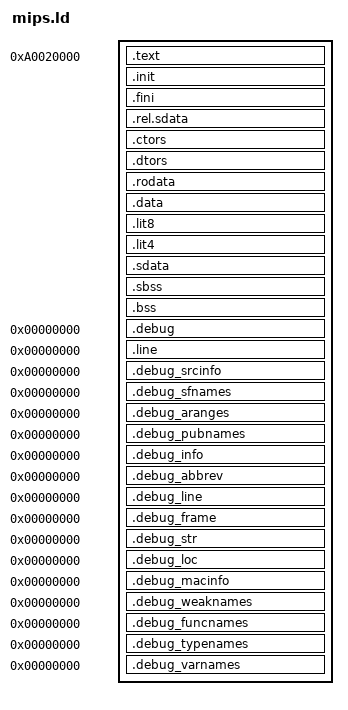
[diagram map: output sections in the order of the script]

ENTRY(_start)
OUTPUT_FORMAT("elf32-bigmips", "elf32-bigmips", "elf32-littlemips")
GROUP(-lc -lidt -lgcc)
SEARCH_DIR(.)
__DYNAMIC  =  0;

/*
 * Allocate the stack to be at the top of memory, since the stack
 * grows down
 */
PROVIDE (__stack = 0);
/* PROVIDE (__global = 0); */

SECTIONS
{	
  . = 0xA0020000;
  .text : {
    _ftext = . ;
    PROVIDE (eprol = .);
    *(.text)
    *(.text.*)
    *(.gnu.linkonce.t*)
    *(.mips16.fn.*)
    *(.mips16.call.*)
  }
  .init : {
    *(.init)
  }
  .fini : {
    *(.fini)
  }
  .rel.sdata : {
    PROVIDE (__runtime_reloc_start = .);
    *(.rel.sdata)
    PROVIDE (__runtime_reloc_stop = .);
  }
  PROVIDE (etext = .);
  _etext  =  .;
  
  .ctors    :
  {
  }

  .dtors    :
  {
  }

  . = .;
  .rodata : {
    *(.rdata)
    *(.rodata)
    *(.rodata.*)
    *(.gnu.linkonce.r*)
  }
   _fdata = ALIGN(16);
  .data : {
    *(.data)
    *(.data.*)
    *(.gnu.linkonce.d*)
  }
  . = ALIGN(8);
  _gp = . + 0x8000;
  __global = _gp;
  .lit8 : {
    *(.lit8)
  }
  .lit4 : {
    *(.lit4)
  }
  .sdata : {
    *(.sdata)
    *(.sdata.*)
    *(.gnu.linkonce.s*)
  }
  . = ALIGN(4);
   PROVIDE (edata  =  .);
   _edata  =  .;
   _fbss = .;
  .sbss : {
    *(.sbss)
    *(.scommon)
  }
  .bss : {
    _bss_start = . ;
    *(.bss)
    *(COMMON)
  }

  PROVIDE (end = .);
  _end = .;

  /* DWARF debug sections.
     Symbols in the DWARF debugging sections are relative to 
     the beginning of the section so we begin them at 0.  */

  /* DWARF 1 */
  .debug          0 : { *(.debug) }
  .line           0 : { *(.line) }

  /* GNU DWARF 1 extensions */
  .debug_srcinfo  0 : { *(.debug_srcinfo) }
  .debug_sfnames  0 : { *(.debug_sfnames) }

  /* DWARF 1.1 and DWARF 2 */
  .debug_aranges  0 : { *(.debug_aranges) }
  .debug_pubnames 0 : { *(.debug_pubnames) }

  /* DWARF 2 */
  .debug_info     0 : { *(.debug_info) }
  .debug_abbrev   0 : { *(.debug_abbrev) }
  .debug_line     0 : { *(.debug_line) }
  .debug_frame    0 : { *(.debug_frame) }
  .debug_str      0 : { *(.debug_str) }
  .debug_loc      0 : { *(.debug_loc) }
  .debug_macinfo  0 : { *(.debug_macinfo) }

  /* SGI/MIPS DWARF 2 extensions */
  .debug_weaknames 0 : { *(.debug_weaknames) }
  .debug_funcnames 0 : { *(.debug_funcnames) }
  .debug_typenames 0 : { *(.debug_typenames) }
  .debug_varnames  0 : { *(.debug_varnames) }
}
